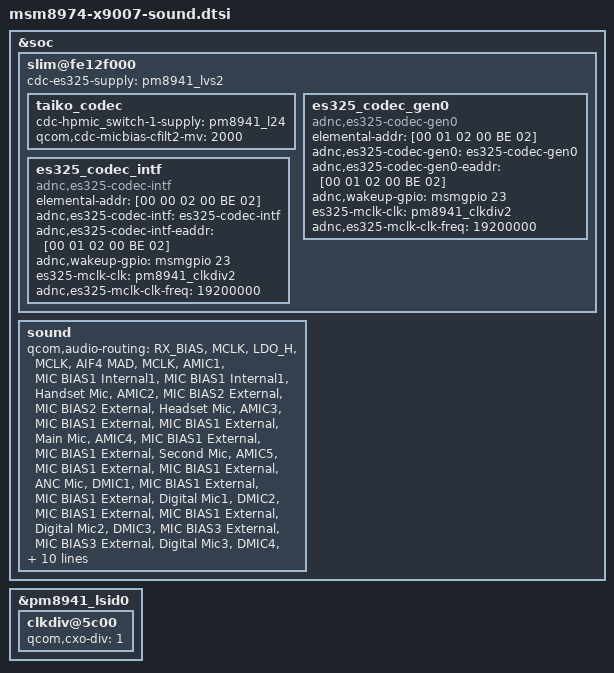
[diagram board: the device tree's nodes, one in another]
/* Copyright (c) 2012-2013, The Linux Foundation. All rights reserved.
 *
 * This program is free software; you can redistribute it and/or modify
 * it under the terms of the GNU General Public License version 2 and
 * only version 2 as published by the Free Software Foundation.
 *
 * This program is distributed in the hope that it will be useful,
 * but WITHOUT ANY WARRANTY; without even the implied warranty of
 * MERCHANTABILITY or FITNESS FOR A PARTICULAR PURPOSE.  See the
 * GNU General Public License for more details.
 */

&soc {
	slim@fe12f000 {
		cdc-es325-supply = <&pm8941_lvs2>;

		taiko_codec {
			cdc-hpmic_switch-1-supply = <&pm8941_l24>;
			qcom,cdc-micbias-cfilt2-mv = <2000>;
		};

		es325_codec_gen0 {
			compatible = "adnc,es325-codec-gen0";
			elemental-addr = [00 01 02 00 BE 02];

			adnc,es325-codec-gen0 = "es325-codec-gen0";
			adnc,es325-codec-gen0-eaddr = [00 01  02 00 BE 02];

			adnc,wakeup-gpio = <&msmgpio 23 0>;

			es325-mclk-clk =  <&pm8941_clkdiv2>;
			adnc,es325-mclk-clk-freq = <19200000>;
		};

		es325_codec_intf {
			compatible = "adnc,es325-codec-intf";
			elemental-addr =  [00 00 02 00 BE 02];

			adnc,es325-codec-intf ="es325-codec-intf";
			adnc,es325-codec-intf-eaddr = [00 01 02 00 BE 02];

			adnc,wakeup-gpio = <&msmgpio 23 0>;/* DEFINED BY CUSTOMER*/

			es325-mclk-clk = <&pm8941_clkdiv2>;
			adnc,es325-mclk-clk-freq = <19200000>;
		};
	};

	sound {
		qcom,audio-routing =
			"RX_BIAS", "MCLK",
			"LDO_H", "MCLK",
			"AIF4 MAD", "MCLK",
			"AMIC1", "MIC BIAS1 Internal1",
			"MIC BIAS1 Internal1", "Handset Mic",
			"AMIC2", "MIC BIAS2 External",
			"MIC BIAS2 External", "Headset Mic",

			"AMIC3", "MIC BIAS1 External",
			"MIC BIAS1 External", "Main Mic",
			"AMIC4", "MIC BIAS1 External",
			"MIC BIAS1 External", "Second Mic",
			"AMIC5", "MIC BIAS1 External",
			"MIC BIAS1 External", "ANC Mic",

			"DMIC1", "MIC BIAS1 External",
			"MIC BIAS1 External", "Digital Mic1",
			"DMIC2", "MIC BIAS1 External",
			"MIC BIAS1 External", "Digital Mic2",
			"DMIC3", "MIC BIAS3 External",
			"MIC BIAS3 External", "Digital Mic3",
			"DMIC4", "MIC BIAS3 External",
			"MIC BIAS3 External", "Digital Mic4",
			"DMIC5", "MIC BIAS4 External",
			"MIC BIAS4 External", "Digital Mic5",
			"DMIC6", "MIC BIAS4 External",
			"MIC BIAS4 External", "Digital Mic6";

		qcom,hpmic-switch-gpio = <&msmgpio 87 0>;
		qcom,yda145_ctr-gpio = <&msmgpio 77 0>;
		qcom,yda145_boost-gpio = <&msmgpio 67 0>;
		enable_spk-gpio = <&msmgpio 73 0>;
		cdc_spk-supply = <&pm8941_boost>;
	};
};

&pm8941_lsid0 {
	clkdiv@5c00 {
		qcom,cxo-div = <1>;
	};
};
